# RL7005_IP_SVD register map
Vendor: Realtek
Registers are 32-bit, read-write, reset 0x0 unless marked. A register's access mark holds for its fields unless they carry their own. Offsets are from the block's base; [hi:lo] are bit positions; {n}, {i} and the like mark numbered series.

## PAGE6 (part 1 of 2)
Base 0x40000000
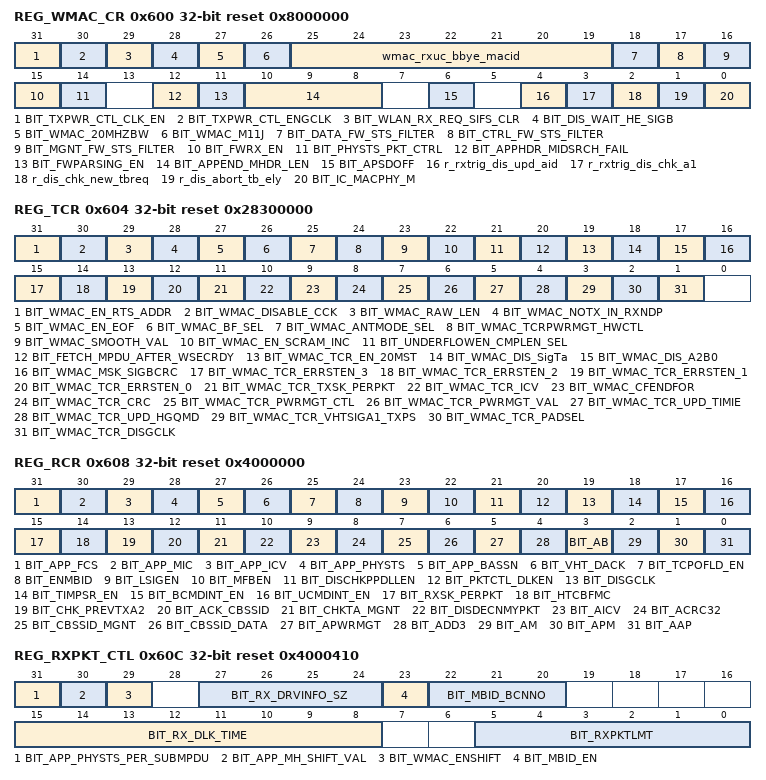
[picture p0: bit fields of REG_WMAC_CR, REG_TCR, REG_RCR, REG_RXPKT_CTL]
0x600 REG_WMAC_CR access per field reset 0x8000000
  [31] BIT_TXPWR_CTL_CLK_EN rw — IF set to 1, txpwr_ctrl clock enable, only work when BIT_TXPWR_CTL_ENGCLK set to 1,
  [30] BIT_TXPWR_CTL_ENGCLK rw — If set to 1, enable txpwr_ctrl clock gating function.
  [29] BIT_WLAN_RX_REQ_SIFS_CLR rw — When set, enable sifs clear wlan_rx_req
  [28] BIT_DIS_WAIT_HE_SIGB rw — When set, will not wait and check he mu sigb and ndp info
  [27] BIT_WMAC_20MHZBW rw
  [26] BIT_WMAC_M11J rw
  [25:19] wmac_rxuc_bbye_macid ro — hw latch macid when rx my unicast bye-bye frame in relay mode 7E:rxpktbuf full 7F:not valid macid
  [18] BIT_DATA_FW_STS_FILTER rw — When this bit is set,Accept data frame in partial length condition. It will take effect when RxFilter3-5 is disabled and RxFilter 0-2 is enabled.
  [17] BIT_CTRL_FW_STS_FILTER rw — When this bit is set,Accept control frame in partial length condition. It will take effect when RxFilter3-5 is disabled and RxFilter 0-2 is enabled.
  [16] BIT_MGNT_FW_STS_FILTER rw — When this bit is set,Accept management frame in partial length condition. It will take effect when RxFilter3-5 is disabled and RxFilter 0-2 is enabled.
  [15] BIT_FWRX_EN rw — Enable to receive pkt into FWFF, default 1'b0. When Fw needs to receive pkt, this bit must be set to 1'b1
  [14] BIT_PHYSTS_PKT_CTRL rw — If set to 1,HW will send interrupt (0x124[26]) only when there is phy status valid fwsts pkt written into FWFF
  [12] BIT_APPHDR_MIDSRCH_FAIL rw — If set to 1, Hw will append 16 bytes MAC header into FWFF when MACID search fail
  [11] BIT_FWPARSING_EN rw — If set to 1, mac header and rx desc of the pkt into rx buff are also received into FWFF.
  [10:8] BIT_APPEND_MHDR_LEN rw — Appended MAC header length, unit in 32 bytes
  [6] BIT_APSDOFF rw — 1:MAC issue sleep signal to disable BB/AFE/RF TRX function. After MAC has finished, APSDOFF_STATUS will report"1". 0:MAC issue wakeup signal to recall BB/AFE/RF back to RX idle mode. After MAC has finished,APSDOFF _STATUS will report "0".
  [4] r_rxtrig_dis_upd_aid rw — 1:will only update aid_fit info when the first trigger in a ppdu is parsered 0:will update aid_fit info every time when two or more trigger aggregate in a ppdu
  [3] r_rxtrig_dis_chk_a1 rw — 1:will not check if A1 of trigger frame is my unicast or broadcast address 0:will check if A1 of trigger frame is my unicast or broadcast address
  [2] r_dis_chk_new_tbreq rw — 1:rxtrig req_in will assert every time when aid fit if two or more trigger aggregate in a ppdu 0:rxtrig req_in will not assert again when there is already a correct trigger received
  [1] r_dis_abort_tb_ely rw — 1:will abort ptcl generating tb data when macrx_active is low 0:will abort ptcl generating tb data when new rxtrig req_in is assert
  [0] BIT_IC_MACPHY_M rw — To make ASIC become BB+RF only, and put out the MAC_PHY interface
0x604 REG_TCR reset 0x28300000 — Transmission Configuration Register
  [31] BIT_WMAC_EN_RTS_ADDR — when set to 1, enable change RTS multicast address
  [30] BIT_WMAC_DISABLE_CCK — when set to 1, disable cck rate packet
  [29] BIT_WMAC_RAW_LEN — 1: use raw ppdu_len 0: use 4byte alignment ppdu_len
  [28] BIT_WMAC_NOTX_IN_RXNDP — 1: block original tx when receiving NDP packet
  [27] BIT_WMAC_EN_EOF — when set to 1, enable single ampdu for qos packet. In early mode,not set to 1.
  [26] BIT_WMAC_BF_SEL — 1: set ndp_rx_standby when rx ppdu of ndpa end; 0: set ndp_rx_standby when rx ndpa packet fcs end;
  [25] BIT_WMAC_ANTMODE_SEL — 0:4x1 mode, 1:8x1 mode
  [24] BIT_WMAC_TCRPWRMGT_HWCTL — If this bit is set to 1, MAC will overwrite power bit of frame control according to PWR_ST. (only for RTS/CTS/ACK/CFEND/BA/BAR frames)
  [23] BIT_WMAC_SMOOTH_VAL — smooth value of plcp header HTSIG2
  [22] BIT_WMAC_EN_SCRAM_INC — Increase 1 in service field scrambler seed per tx end
  [21] BIT_UNDERFLOWEN_CMPLEN_SEL — compare length selector for enable condition of underflow, consider plcp header when set 1
  [20] BIT_FETCH_MPDU_AFTER_WSECRDY — If set to 1,mactx_mpdu_gen will fetch mpdu after wsec is ready when sectype is not tkip/wep40/wep104
  [19] BIT_WMAC_TCR_EN_20MST — when set to 1, enable ndpa signaling TA when BW =20MHz
  [18] BIT_WMAC_DIS_SigTa — when set to 1, disable signaling TA information for response packet
  [17] BIT_WMAC_DIS_A2B0 — when set to 1, not check bit 0 of rx a2
  [16] BIT_WMAC_MSK_SIGBCRC — when set to 1, mask sigb crc in service field for vht packet
  [15] BIT_WMAC_TCR_ERRSTEN_3 — Use phytxend_ps to reset mactx state machine
  [14] BIT_WMAC_TCR_ERRSTEN_2 — If txd fifo underflow when txtype is cmpba, reset mactx state machine
  [13] BIT_WMAC_TCR_ERRSTEN_1 — If txd fifo underflow, reset mactx state machine
  [12] BIT_WMAC_TCR_ERRSTEN_0 — Phytxend_ps comes but mactx still active, reset mactx state machine
  [11] BIT_WMAC_TCR_TXSK_PERPKT — Search key for each mpdu
  [10] BIT_WMAC_TCR_ICV — Integrity Check Value. This bit indicates the existence of an ICV appended to an encipherment packet. 1: No ICV appended 0: ICV appended
  [9] BIT_WMAC_CFENDFOR — CF-End Frame Format.The Address 2 field of CF-End is defined to be the address of the STA contained in the AP, but in 802.11n a STA can also send CF-End.The Address 2 field is not specified clearly in this case. This register chooses between MAC ID of the STA or BSSID of the network. 0: BSSID 1: MAC ID
  [8] BIT_WMAC_TCR_CRC — Append 32-bit Cyclic Redundancy Check. This bit indicates the existence of a CRC32 appended to a packet. 1: No CRC32 appended 0: A CRC32 is appended
  [7] BIT_WMAC_TCR_PWRMGT_CTL — If this bit is set to 1, MAC will overwrite power bit of frame control according to PWR_ST. (only for data frame)
  [6] BIT_WMAC_TCR_PWRMGT_VAL — MAC will overwrite power bit of frame control according to PWR_ST.(only for data frame)
  [5] BIT_WMAC_TCR_UPD_TIMIE — when set to 1, enable hw to update beacon's time field
  [4] BIT_WMAC_TCR_UPD_HGQMD — when set to 1, enable HGQ set moredata bit in Frame control field
  [3] BIT_WMAC_TCR_VHTSIGA1_TXPS — This bit controls TXOP_PS_NOT_ALLOWED bit value of VHT-SIG-A1 field in TX VHT packets 1: TXOP_PS_NOT_ALLOWED is set to 1 0: TXOP_PS_NOT_ALLOWED is set to 0
  [2] BIT_WMAC_TCR_PADSEL — AMPDU Padding pattern selection 0: 32-bit Zero padding, 1: Zero length delimiter.
  [1] BIT_WMAC_TCR_DISGCLK — when set to 1,disable MACTX clock gating control.
0x608 REG_RCR reset 0x4000000 — Receive Configuration Register
  [31] BIT_APP_FCS — When set, wmac RX will append FCS after payload.
  [30] BIT_APP_MIC — When this bit is set to 1, MACRX will retain the MIC at the bottom of the packet. Otherwise, MIC will be removed and reported the status in RXDESC. When a MPDU is encrypted with TKIP without MIC, MACRX will ignore this option, that is, MIC must be remained in back of the plain text.
  [29] BIT_APP_ICV — When this bit is set to 1, MACRX will retain the ICV at the bottom of the packet. Otherwise, MIC will be removed and reported the status in RXDESC.
  [28] BIT_APP_PHYSTS — Append RXFF0 PHY Status Enable When this bit is set, then PHY Status is appended before RX packet in RXFF. When this bit is set, the RX_DRV_INFO_SZ shall be set to include PHY Status report.
  [27] BIT_APP_BASSN — Append SSN of previous TXBA Enable When this bit is set, then SSN of previous TXBA is appended as after original RXDESC as the 4-th DW of RXDESC.
  [26] BIT_VHT_DACK — This bit to control response type for vht single mpdu data packet. 1: ACK as response 0: BA as response
  [25] BIT_TCPOFLD_EN — When set,Enable TCP checksum offload
  [24] BIT_ENMBID — Enable Multiple Bssid. 1: Enable. Only response ACK to the packets whose DID(A1) matching to the addresses in the MBSSID CAM Entries. 0: Disable.
  [23] BIT_LSIGEN — Enable LSIG TXOP Protection function. 1: Enable. Search KEYCAM for each rx packet to check if LSIGEN bit is set. If LSIGEN is set, then sender support LSIG TXOP protection and we need send response with LSIG TXOP protection 0: Disable
  [22] BIT_MFBEN — Enable immediate MCS Feedback function 1: Enable. When Rx packet with MRQ = 1"b1, then search KEYCAM to find sender"s MCS Feedback function and send response 0: Disable
  [21] BIT_DISCHKPPDLLEN — When set,do not check PPDU while the PPDU length is smaller than 14 byte.
  [20] BIT_PKTCTL_DLKEN — When set,while rx path dead lock occurs, reset rx path
  [19] BIT_DISGCLK — When set,disable macrx clock gating control
  [18] BIT_TIMPSR_EN — When set, enable RX Beacon TIM Parser
  [17] BIT_BCMDINT_EN — Broadcast data packet interrupt enable. When this bit is set, this bit is auto clear by MAC. As long as a data type broadcast packet is received, this bit will be set.
  [16] BIT_UCMDINT_EN — Unicast data packet with FC.MD = 1 interrupt enable. When this bit is set, this bit is auto clear by MAC. As long as a data type unicast packet is received, this bit will be set.
  [15] BIT_RXSK_PERPKT — Executing key search per MPDU
  [14] BIT_HTCBFMC — 1: HTC -> MFC 0: MFC-> HTC
  [13] BIT_CHK_PREVTXA2 — When set,enable check rxa1 with txa2.
  [12] BIT_ACK_CBSSID — The field effects behavior of response frame,except TB. 0:Only A1 match to send response frame. 1:A1 match and satisfy BSSID condition will send response frame.
  [11] BIT_CHKTA_MGNT — Check Transmitter_BCN When set to 1, MAC will check the Transmitter Address (A2) of RX beacon or Probe response to determine if this packet belongs to this Transmitter Address (Address 2) . Both in Infrastructure mode and Ad-hoc mode.
  [10] BIT_DISDECNMYPKT — This bit determines whether hw need to do decryption. 1: If A1 match or broadcast, do decryption. 0: Do decryption.
  [9] BIT_AICV — Accept Integrity Check Value Error packets. This bit determines whether packets with ICV errors will be accepted or rejected. 1: Accept 0: Reject
  [8] BIT_ACRC32 — Accept CRC32 Error packets. When set to 1, packets with CRC32 errors will be accepted. When set to 0, packets with CRC32 errors will be rejected. 1: Accept 0: Reject
  [7] BIT_CBSSID_MGNT — Check BSSID_BCN When set to 1, MAC will check the BSSID of RX beacon or Probe response to determine if this packet belongs to this BSSID.
  [6] BIT_CBSSID_DATA — Check BSSID_DATA, To DS, From DS Match Packet. When set to 1, MAC will check the Rx data type frame"s BSSID, To DS, and From DS fields, to determine if it is set to Link OK in an Infrastructure or Ad hoc network. Note this setting is independent of nettype. Driver must set this bit in ad hoc mode and client mode.
  [5] BIT_APWRMGT — Accept Power Management Packet. This bit determines whether the RTL8192D will accept or reject packets with the power management bit set. 1: Accept 0: Reject
  [4] BIT_ADD3 — Accept Address 3 Match Packets. Set this bit to 1 to accept broadcast/multicast data type frames that Address 3 matching RTL8190"s MAC address. This bit is valid only when NETYPE (bit 3-2, MSR) is set to Link OK on an Infrastructure network.
  [3] BIT_AB — Accept Broadcast packets. This bit determines whether broadcast packets will be accepted or rejected. 1: Accept 0: Reject
  [2] BIT_AM — Accept Multicast packets. This bit determines whether multicast packets will be accepted or rejected. 1: Accept 0: Reject
  [1] BIT_APM — Accept Physical Match packets. This bit determines whether physical match packets will be accepted or rejected. 1: Accept 0: Reject
  [0] BIT_AAP — Accept Destination Address packets. This bit determines whether packets with a destination address will be accepted or rejected. 1: Accept 0: Reject
0x60C REG_RXPKT_CTL reset 0x4000410 — RX Packet Control Register
  [31] BIT_APP_PHYSTS_PER_SUBMPDU — When this bit is set to 1,append phy status for each mpdu if phy status is valid. Otherwise,append phy status for each ppdu.
  [30] BIT_APP_MH_SHIFT_VAL — When this bit is set to 1,append MAC header shift value in rx descriptor,otherwise, not append
  [29] BIT_WMAC_ENSHIFT — MAC header shift function enable signal in MACRX
  [27:24] BIT_RX_DRVINFO_SZ — RX DESC Driver Info Size: For RXPKTBUF layout, this field indicates the offset starting from the end of RXDESC to the beginning of RX packet. The unit is 8-byte. This value will be copied to DRV_INFO_SIZE field in RXDESC.
  [23] BIT_MBID_EN
  [22:20] BIT_MBID_BCNNO
  [15:8] BIT_RX_DLK_TIME — macrx dead lock timer timeout value (unit in 4us). As data_on is deasserted and no RXD is received but macrx still waits coming RXD, the deadlock timer will be enabled in this case
  [5:0] BIT_RXPKTLMT — RX PKT Upper Limit. The unit is 512 bytes. When "0", no RX limit is forced.
0x610 REG_MACID — MAC ID Register
  [31:0] BIT_MACID_V1 — MAC Identification Number Register BIT[31:0]
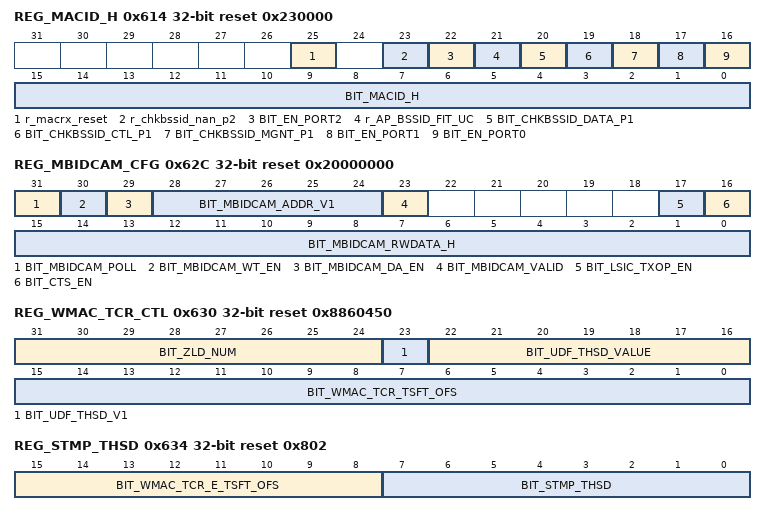
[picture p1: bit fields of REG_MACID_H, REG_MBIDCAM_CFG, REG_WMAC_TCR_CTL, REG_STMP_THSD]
0x614 REG_MACID_H access per field reset 0x230000 — MAC ID Register
  [25] r_macrx_reset wo — set 1 to reset macrx.One pulse
  [23] r_chkbssid_nan_p2 rw — When set 1,enable check port2 bssid.
  [22] BIT_EN_PORT2 rw — When set 1,enable NAN PORT2
  [21] r_AP_BSSID_FIT_UC rw — When set 1,bssid fit when AP port0 rx unciast data packet
  [20] BIT_CHKBSSID_DATA_P1 rw — When set,enable check port1 data frame bssid
  [19] BIT_CHKBSSID_CTL_P1 rw — When set,enable check port1 bssid of trigger/vhtndpa/hendpa/ba
  [18] BIT_CHKBSSID_MGNT_P1 rw — When set,enable check port1 mgnt frame bssid
  [17] BIT_EN_PORT1 rw — When set 1,enable PORT1
  [16] BIT_EN_PORT0 rw — When set 1,enable PORT0
  [15:0] BIT_MACID_H rw — MAC Identification Number Register BIT[47:32]
0x618 REG_BSSID — BSSID Register
  [31:0] BIT_BSSID_V1 — Basic Station Set Identification BIT[31:0]
0x61C REG_BSSID_H — BSSID Register
  [15:0] BIT_BSSID_H — Basic Station Set Identification BIT[47:32]
0x620 REG_MAR — Multicast Address Register
  [31:0] BIT_MAR_V1 — Multicast Address Register BIT[31:0]. The value of this register is written by the driver to specify the type of multicast address supported by RTL8192D. The value is created by a hashed calculation that is also implemented by the hardware for multicast address filtering.
0x624 REG_MAR_H — Multicast Address Register
  [31:0] BIT_MAR_H — Multicast Address Register BIT[63:32].The value of this register is written by the driver to specify the type of multicast address supported by RTL8192D. The value is created by a hashed calculation that is also implemented by the hardware for multicast address filtering.
0x628 REG_MBIDCAMCFG_1 — MBSSID CAM Configuration Register
  [31:0] BIT_MBIDCAM_WDATA_L — BSSID[31:0]
0x62C REG_MBIDCAM_CFG access per field reset 0x20000000 — MBSSID CAM Configuration Register
  [31] BIT_MBIDCAM_POLL wo — Pooling bit.
  [30] BIT_MBIDCAM_WT_EN rw — Write Enable.
  [29] BIT_MBIDCAM_DA_EN rw — CAM Direct Acess Enable
  [28:24] BIT_MBIDCAM_ADDR_V1 rw — CAM Address
  [23] BIT_MBIDCAM_VALID rw — CAM Valid bit.
  [17] BIT_LSIC_TXOP_EN rw — LSIG TXOP enable
  [16] BIT_CTS_EN rw — Dual CTS/CFE enable
  [15:0] BIT_MBIDCAM_RWDATA_H rw — BSSID[47:32]
0x630 REG_WMAC_TCR_CTL reset 0x8860450
  [31:24] BIT_ZLD_NUM — Fetch zero length delimiter number(unit : 4bytes) when mactx underflow
  [23] BIT_UDF_THSD_V1 — BIT_UDF_THSD[7]=1,enable underflow recovery;r_UDF_THSD[7]=0,disable underflow recovery; BIT_UDF_THSD[6:0]: when mac_wrptr - PHY_rdptr is less than this value, set underflow;
  [22:16] BIT_UDF_THSD_VALUE — Underflow threshold
  [15:0] BIT_WMAC_TCR_TSFT_OFS — BIT_WMAC_TCR_TSFT_OFS[7:0] is for cck stamp time offset; BIT_WMAC_TCR_TSFT_OFS[15:8] is for ofdm rate time offset;
0x634 REG_STMP_THSD reset 0x802
  [15:8] BIT_WMAC_TCR_E_TSFT_OFS — BIT_WMAC_TCR_TSFT_OFS[7:0] is for ht/vht/he stamp time offset;
  [7:0] BIT_STMP_THSD — when PHY_rdptr is greater than this value, then latch STMP value from TSFT
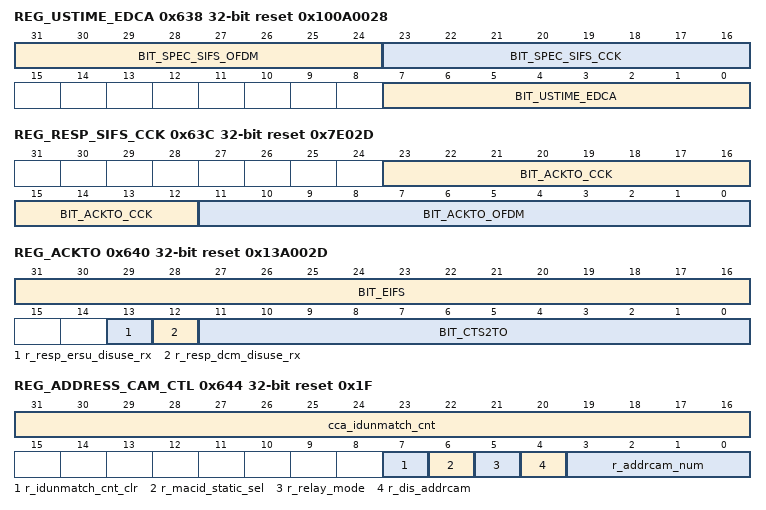
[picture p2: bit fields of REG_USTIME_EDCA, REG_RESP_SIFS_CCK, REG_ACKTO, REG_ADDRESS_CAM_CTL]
0x638 REG_USTIME_EDCA reset 0x100A0028 — US Time Tuning for EDCA Register
  [31:24] BIT_SPEC_SIFS_OFDM — The spec SIFS value for duration calculation
  [23:16] BIT_SPEC_SIFS_CCK — The spec SIFS value for duration calculation
  [7:0] BIT_USTIME_EDCA — Sets the microsecond time unit used by MAC EDCA clock.
0x63C REG_RESP_SIFS_CCK reset 0x7E02D — Response SIFS for CCK Register
  [23:12] BIT_ACKTO_CCK — This register sets the Ack time out value after Tx unicast packet with CCK rate. It is in units of us.
  [11:0] BIT_ACKTO_OFDM — This register sets the Ack time out value after Tx unicast packet. It is in units of us.
0x640 REG_ACKTO reset 0x13A002D — ACK Timeout Register
  [31:16] BIT_EIFS — This register sets the EIFS value mentioned in 802.11 specification. It is in units of us. To receive 1Mbps ACK frame, EIFS = SIFS + 144us (preamble length) + 48us (PLCP header length) + 112us (14 bytes of data) = 314us.
  [13] r_resp_ersu_disuse_rx — 0:rx er su will response tx er su
  [12] r_resp_dcm_disuse_rx — 0:rx dcm will response tx dcm when ctrl info is valid and inf0_dcm=1
  [11:0] BIT_CTS2TO — This register sets the CTS2 time out value after CTS1 in Dual CTS sequence. It is in units of us.
0x644 REG_ADDRESS_CAM_CTL access per field reset 0x1F
  [31:16] cca_idunmatch_cnt ro — macid no match counter for mpdu
  [7] r_idunmatch_cnt_clr wo — when set, generate one pulse and reset cca_idunmatch_cnt
  [6] r_macid_static_sel rw — when set, statistic only A1 match packet;otherwise statistic A1 match and my bc/mc packet for macid_match_no_fcs
  [5] r_relay_mode rw — when set, enable relay mesh function
  [4] r_dis_addrcam rw — when set, disable address cam filter function
  [3:0] r_addrcam_num rw — address filter cam number, up to 16 entries
0x648 REG_TXOPOWNER_L reset 0x80010
  [31:0] r_txopowner_addr_l — txopowner mac address Register BIT[31:0]
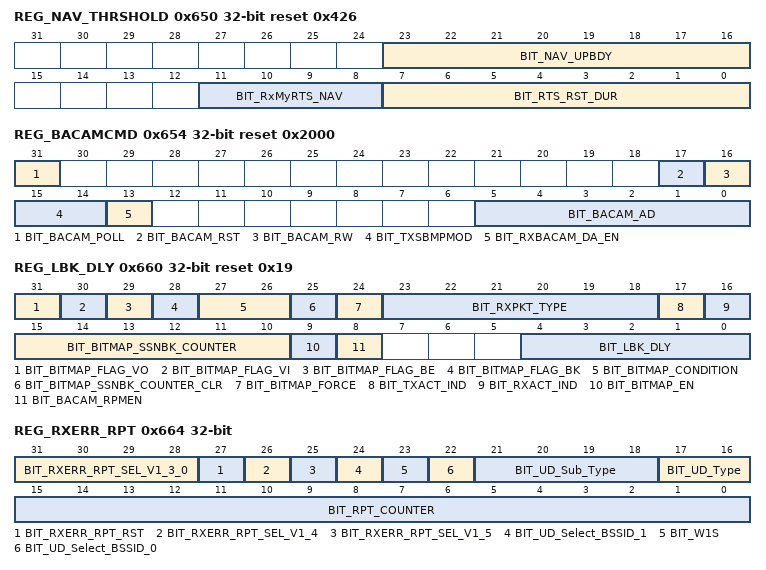
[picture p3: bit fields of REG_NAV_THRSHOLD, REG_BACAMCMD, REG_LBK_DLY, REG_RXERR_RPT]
0x650 REG_NAV_THRSHOLD reset 0x426 — NAV Threshold Register
  [23:16] BIT_NAV_UPBDY — When NAV update is beyond this value, then NAV update is aborted. When this field is 0x00, NAV_UPPER function is disable. The unit is 128us.
  [11:8] BIT_RxMyRTS_NAV — RX my RTS NAV. As rx my unicast RTS and RxMyRTS_NAV is not equal to zero, then rx NAV is set to wait response transition time and RxMyRTS_NAV to avoid contention with the TXOP originator. If RxMyRTS_NAV is equal to zero, this mechanism is disabled
  [7:0] BIT_RTS_RST_DUR — RTS NAV Reset Time. This is the value in us, not including the time of CTS frame, to reset the NAV set by an RTS frame if no PHY indication occurred during this time. Refer to 802.11 1999 Section 9.2.5.4 for detailed description.
0x654 REG_BACAMCMD access per field reset 0x2000 — Block ACK CAM Command Register
  [31] BIT_BACAM_POLL wo — Polling bit BA CAM
  [17] BIT_BACAM_RST ro — Set 1 to reset BA CAM. Hardware will set the invalid bit for all entries. After reset is finished this bit is reset to 0.
  [16] BIT_BACAM_RW rw — Set 1 = Write, set 0 = Read
  [15:14] BIT_TXSBMPMOD rw — Bit[15]: if macrx_dma idle, grant txsbmp_req Bit[14]: if macrx is idle, grant txsbmp_req 00: If FSM is idle, grant txsbmp_req 01: If FSM and mac rx is idle, grant txsbmp_req 10: If FSM and macrx_dma is idle, grant txsbmp_req 11: if FSM, macrx and macrx_dma is idle, grant txsbmp_req
  [13] BIT_RXBACAM_DA_EN rw — CAM Direct Acess enable
  [5:0] BIT_BACAM_AD rw — BA CAM address. Memory is double-word access.
0x658 REG_BACAM_WD — Block ACK CAM Content Register
  [31:0] BIT_BA_CONTENT_L — Used for CAM content read and write access register. Because BA CAM is 64 bit access, the double word (32-bit) responds to the lower 32 bits of CAM content.
0x65C REG_BACAM_WD_H — Block ACK CAM Content Register
  [31:0] BIT_BA_CONTENT_H — Used for CAM content read and write access register. Because BA CAM is 64 bit access, the double word (32-bit) responds to the upper 32 bits of CAM content.
0x660 REG_LBK_DLY access per field reset 0x19 — Loopback Delay Register
  [31] BIT_BITMAP_FLAG_VO ro — When BIT_BITMAP_VO = 1, HW will check received packet's sequence number by BIT_BITMAP_CONDITION, and clear the bit after occur one time which received the correct sequence number.
  [30] BIT_BITMAP_FLAG_VI ro — When BIT_BITMAP_VI = 1, HW will check received packet's sequence number by BIT_BITMAP_CONDITION, and clear the bit after occur one time which received the correct sequence number.
  [29] BIT_BITMAP_FLAG_BE ro — When BIT_BITMAP_BE = 1, HW will check received packet's sequence number by BIT_BITMAP_CONDITION, and clear the bit after occur one time which received the correct sequence number.
  [28] BIT_BITMAP_FLAG_BK ro — When BIT_BITMAP_BK = 1, HW will check received packet's sequence number by BIT_BITMAP_CONDITION, and clear the bit after occur one time which received the correct sequence number.
  [27:26] BIT_BITMAP_CONDITION rw — ADDBA condition: 0: HW start sequence - 64. 1: HW start sequence - 128. 2: HW start sequence - 256. 3: HW start sequence - 512.
  [25] BIT_BITMAP_SSNBK_COUNTER_CLR ro — Clear BIT_BITMAP_SSNBK_COUNTER.
  [24] BIT_BITMAP_FORCE rw — Under the BIT_BITMAP_EN = 1 condition. 1: Rx's packet always checks sequence number by BIT_BITMAP_CONDITION. 0: Disable
  [23:18] BIT_RXPKT_TYPE ro — The type and subtype field of frame control of rx packet
  [17] BIT_TXACT_IND ro — Indicate MAC/PHY is busy to tx packet
  [16] BIT_RXACT_IND ro — Indicate MAC is busy to rx packet
  [15:10] BIT_BITMAP_SSNBK_COUNTER ro — Count the sequence number out of BITMAP condition (0x663[3:2]).
  [9] BIT_BITMAP_EN rw — 1:Enable of counter and WMAC_BITMAP_CTL(0x663) 0:Disable function
  [8] BIT_BACAM_RPMEN rw — 1:Enable repeat mode 0:Disable function
  [4:0] BIT_LBK_DLY rw — Loopback Delay. In unit of 'us'; indicates the delay after which the tdrdy_mac starts. In wep/tkip mode, the delay should be larger than 15, because the initial delay of security is about 1320 cycles, approximately to 16.5 us.
0x664 REG_RXERR_RPT access per field — RX Error Report Register
  [31:28] BIT_RXERR_RPT_SEL_V1_3_0 rw — Rx packet counter report selection bit3~bit0 RXERR_RPT_SEL[25,26,31:28]: Counter description 6'd0: OFDM MPDU OK counter 6'd1: OFDM MPDU Fail counter 6'd2: OFDM False Alarm counter 6'd3: CCK MPDU OK counter 6'd4: CCK MPDU Fail counter 6'd5: CCK False Alarm counter; 6'd6: HT MPDU OK counter 6'd7: HT MPDU Fail counter 6'd8: HT PPDU PLCP ok counter 6'd9: HT False Alarm counter 6'd10: Rx full drop packet counter 6'd11: RSVD 6'd12: user define 0 counter 6'd13: user define 1 counter 6'd14: user define 2 counter 6'd15: user define 3 counter 6'd16: VHT SU MPDU OK counter 6'd17: VHT SU MPDU Fail counter 6'd18: VHT SU PPDU plcp ok counter 6'd19: VHT SU False Alarm counter 6'd20: invalid_pkt counter 6'd21: VHT MU MPDU OK counter 6'd22: VHT MU MPDU Fail counter 6'd23: VHT MU PPDU plcp ok counter 6'd24: VHT MU False Alarm counter 6'd25: HE SU MPDU OK counter 6'd26: HE SU MPDU Fail counter 6'd27: HE SU PPDU plcp ok counter 6'd28: HE SU False Alarm counter 6'd29: HE MU MPDU OK counter 6'd30: HE MU MPDU Fail counter 6'd31: HE MU PPDU plcp ok counter 6'd32: HE MU False Alarm counter 6'd33: drop packet counter
  [27] BIT_RXERR_RPT_RST wo — Write "1" to set the counter to zero. One pulse
  [26] BIT_RXERR_RPT_SEL_V1_4 rw — Rx packet counter report selection bit4
  [25] BIT_RXERR_RPT_SEL_V1_5 rw — Rx packet counter report selection bit5
  [24] BIT_UD_Select_BSSID_1 rw — {24,22} Select matched BSSID: 2'b0: Port 0 2'b1: Port 1 otherwise, do not care bssid match or not
  [23] BIT_W1S rw — Write One Setting, it is only valid for RXERR_RPT_SEL (4'd12 ~ 4'd15)
  [22] BIT_UD_Select_BSSID_0 rw — Select BSSID bit0
  [21:18] BIT_UD_Sub_Type rw — User defined: SubType
  [17:16] BIT_UD_Type rw — User defined: Type
  [15:0] BIT_RPT_COUNTER rw — The reported counter value corresponding to Report type selected.
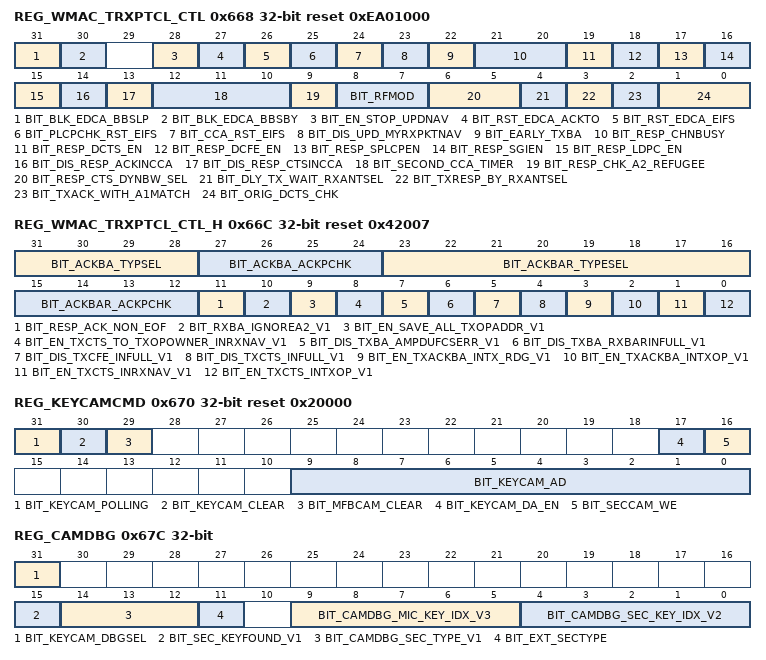
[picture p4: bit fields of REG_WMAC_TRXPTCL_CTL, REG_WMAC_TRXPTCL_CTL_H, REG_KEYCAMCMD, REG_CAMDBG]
0x668 REG_WMAC_TRXPTCL_CTL reset 0xEA01000 — WMAC TX/RX Protocol Control Register
  [31] BIT_BLK_EDCA_BBSLP — Block EDCA Tx while BB in sleep state
  [30] BIT_BLK_EDCA_BBSBY — Block EDCA Tx while BB in standby state
  [28] BIT_EN_STOP_UPDNAV — When this bit set 1. If RX packet with EDCA_REF is low, not update NAV.
  [27] BIT_RST_EDCA_ACKTO — While in ACKTO duration, reset scheduler top to TX
  [26] BIT_RST_EDCA_EIFS — While in EIFS duration, reset scheduler top to TX
  [25] BIT_PLCPCHK_RST_EIFS — Reset EIFS counter while receive correct PLCP.
  [24] BIT_CCA_RST_EIFS — Reset EIFS counter while CCA on
  [23] BIT_DIS_UPD_MYRXPKTNAV — Do not update NAV, while receiving my packet.
  [22] BIT_EARLY_TXBA — While phyrxon down, mac_rxactive on. Ignore mac rx busy, respond BA immediately.
  [21:20] BIT_RESP_CHNBUSY — Define channel busy condition in responder to determine RX busy 1: PHYRXON (OFDM_VBON/CCKCCA) 0: CCA (CCKCCA/OFDMCCA)
  [19] BIT_RESP_DCTS_EN — Enable responder send dual CTS for responding Rx RTS
  [18] BIT_RESP_DCFE_EN — Enable responder send dual CF-END for responding RX CF-END
  [17] BIT_RESP_SPLCPEN — Enable responder send SPLCP CCK response for acknowledging Rx SPLCP CCK packet
  [16] BIT_RESP_SGIEN — Enable responder send SGI HT-OFDM response for acknowledging Rx SGI HT-OFDM packet
  [15] BIT_RESP_LDPC_EN — if rxpkt with ldpc, response pkt with ldpc
  [14] BIT_DIS_RESP_ACKINCCA — Disable to response ack when cca goes high after SIFS
  [13] BIT_DIS_RESP_CTSINCCA — 8812 Disable to response cts when cca goes high after SIFS
  [12:10] BIT_SECOND_CCA_TIMER — 8812 The maximum time interval in us that secondary cca is pull high before primary cca When receive duplicated rts. When station response with cts, if the time that secondary cca pull high before primary cca is larger than this threshold, then secondary cca is judged to be interference, otherwise it is judged to the received RTS frame. default: 3"b0
  [9] BIT_RESP_CHK_A2_REFUGEE — if port 1 isacting as AP,this bit should set 0,otherwise should set 1 if relay mode enable and port1 is not AP mode
  [8:7] BIT_RFMOD — 8812 RF_BW indication, Used to decide response duplicated cts txsc 2"b00: 20M, 2"b01: 40M, 2"b10: 80M e.g: when RF_BW= 80M, duplicated cts BW= 40M, txsc = 9 or 10 when RF_BW = 40M, duplicated cts BW = 40M, txsc = 0
  [6:5] BIT_RESP_CTS_DYNBW_SEL — 8812 Response cts bw selection when dynamic rts frame is received 00: current maximum bw indicated by secondary cca 01: bw fall back by one level based on bw in 2"b00 if not reach 20M 10: bw fall back by one level based on bw in 2"b01 if not reach 20M 11: bw fall back by one level based on bw in 2"b10 if not reach 20M e.g, current maximum bw indicated by secondary_cca is 80M, when set to 2"b00, the response cts bw is 80M, when set to 2"b01, cts bw is 40M, when set to 2"b10 or 2"b11 , cts bw is 20M
  [4] BIT_DLY_TX_WAIT_RXANTSEL — 8188E/8812 In some Cases, the phy status may be received too late to be used in the response frame. Enable this bit to postpone the tx of response frame until the phy status is obtained. Otherwise, If the phy status unavailable for its delay, The IOREG value of 0x06D8[6] will be used as before.
  [3] BIT_TXRESP_BY_RXANTSEL — 8188E/8812 Enable responder send the response frame with the antenna selection information which from the phy status of the previous rx frame.
  [2] BIT_TXACK_WITH_A1MATCH — SET TO 1 :check every bit of a1 of rxpkt when need to response
  [1:0] BIT_ORIG_DCTS_CHK — Txok condition for dual CTS frame exchange: 00: Either one Rx ok 01: 1st one Rx ok 10: 2nd one Rx ok 11: both Rx ok
0x66C REG_WMAC_TRXPTCL_CTL_H reset 0x42007 — WMAC TX/RX Protocol Control Register Higher Bit
  [31:28] BIT_ACKBA_TYPSEL — Determine response type for RX BA, and the definition as the bellow 0: NAV 1: Send ACK ACKBA_TYPESEL[0]: used for Basic BA ACKBA_TYPESEL[1]: used for Compression BA ACKBA_TYPESEL[2]: RSVD ACKBA_TYPESEL[3]: used for MTID BA
  [27:24] BIT_ACKBA_ACKPCHK — If set 1, then check ACK Policy of BA control field to determine whether send response or not. When this bit set to 1 and a. ACK Policy of Rx BA control field is 0, then response type is controlled by ACLBA_TYPESEL. b. ACK Policy of Rx BA control field is 1, then don't send response If set 0, then ignore the ACK policy of RX BA control field and response type controlled by ACKBA_TYPESEL ACKBA_ACKPCHK[0]: used for Basic BA ACKBA_ACKPCHK[1]: used for Compression BA ACKBA_ACKPCHK[2]: RSVD ACKBA_ACKPCHK[3]: used for MTID BA
  [23:16] BIT_ACKBAR_TYPESEL — Determine response type for RX BAR, and the definition as the bellow 00: NAV 01: Send BA 10: Send ACK ACKBAR_TYPESEL[1:0]: used for Basic BAR ACKBAR_TYPESEL[3:2]: used for Compression BAR ACKBAR_TYPESEL[5:4]: RSVD ACKBAR_TYPESEL[7:6]: used for MTID BAR
  [15:12] BIT_ACKBAR_ACKPCHK — If set 1, then check ACK Policy of BAR control field to determine whether send response or not. When this bit set to 1 and a. ACK Policy of Rx BAR control field is 0, then response type is controlled by ACLBAR_TYPESEL. b. ACK Policy of Rx BAR control field is 1, then don't send response If set 0, then ignore the ACK policy of RX BAR control field and response type controlled by ACKBA_TYPESEL ACKBA_ACKPCHK[0]: used for Basic BAR ACKBA_ACKPCHK[1]: used for Compression BAR ACKBA_ACKPCHK[2]: RSVD ACKBA_ACKPCHK[3]: used for MTID BAR
  [11] BIT_RESP_ACK_NON_EOF — response to trigger+mgt with eof=0
  [10] BIT_RXBA_IGNOREA2_V1 — Disable check A2 field of RX BA
  [9] BIT_EN_SAVE_ALL_TXOPADDR_V1
  [8] BIT_EN_TXCTS_TO_TXOPOWNER_INRXNAV_V1 — together with bit41, implement 802.11ac txop owner function
  [7] BIT_DIS_TXBA_AMPDUFCSERR_V1 — Disable to send BA for responding RX AMPDU with FCS error subframe
  [6] BIT_DIS_TXBA_RXBARINFULL_V1 — Disable to send BA for responding RX control wrapper BAR dropped by rxpkbuffer full
  [5] BIT_DIS_TXCFE_INFULL_V1 — Disable to send CF-END for responding RX control wrapper CF-END dropped by rxpktbuffer full. This bit is valid when RESP_DCFE_EN is set to 1
  [4] BIT_DIS_TXCTS_INFULL_V1 — Disable to send CTS for responding RX control wrapper RTS dropped by rxpktbuffer full
  [3] BIT_EN_TXACKBA_INTX_RDG_V1 — If this bit is set, then MAC will Tx ACK/BA to respond previous rx my unicast packets send by another STA during TX RDG
  [2] BIT_EN_TXACKBA_INTXOP_V1 — If this bit is set, then MAC will Tx ACK/BA to respond previous rx my unitcast packets send by another STA during my TXOP
  [1] BIT_EN_TXCTS_INRXNAV_V1 — Enable to send CTS in Rx NAV
  [0] BIT_EN_TXCTS_INTXOP_V1 — Enable to send CTS for responding RX RTS during our TXOP period
0x670 REG_KEYCAMCMD access per field reset 0x20000 — CAM Command Register
  [31] BIT_KEYCAM_POLLING ro — Security CAM Polling
  [30] BIT_KEYCAM_CLEAR ro — Set to 1 to clear all valid bits in CAM. After reset will self clear to 0.
  [29] BIT_MFBCAM_CLEAR ro — Write 1 to clear all MFB value in CAM to 7'h7F. After reset will self clear to 0
  [17] BIT_KEYCAM_DA_EN rw — Security CAM Direct Acess Enable
  [16] BIT_SECCAM_WE rw — Security CAM Write Enable
  [9:0] BIT_KEYCAM_AD rw — Security CAM Address Offset CAM address is organized into 8 double-words/entry.
0x674 REG_KEYCAM_WD — Security CAM Content Register
  [31:0] BIT_KEYCAM_WDATA — Security CAM Write Content
0x678 REG_CAMREAD — CAM Read Register
  [31:0] BIT_CAMR_DATA — Security CAM Read Content
0x67C REG_CAMDBG access per field — CAM Debug Register
  [31] BIT_KEYCAM_DBGSEL rw — Select TX/RX CAM Information. Set to 1 to retrieve latest Tx search result. Set to 0 to retrieve latest Rx search result.
  [15] BIT_SEC_KEYFOUND_V1 ro — Security Key Found in CAM 0: key not found 1: key found
  [14:12] BIT_CAMDBG_SEC_TYPE_V1 ro — Found security key type
  [11] BIT_EXT_SECTYPE ro — Found security key ext_sectype
  [9:5] BIT_CAMDBG_MIC_KEY_IDX_V3 ro — Mic KEY INDEX
  [4:0] BIT_CAMDBG_SEC_KEY_IDX_V2 ro — Security KEY INDEX
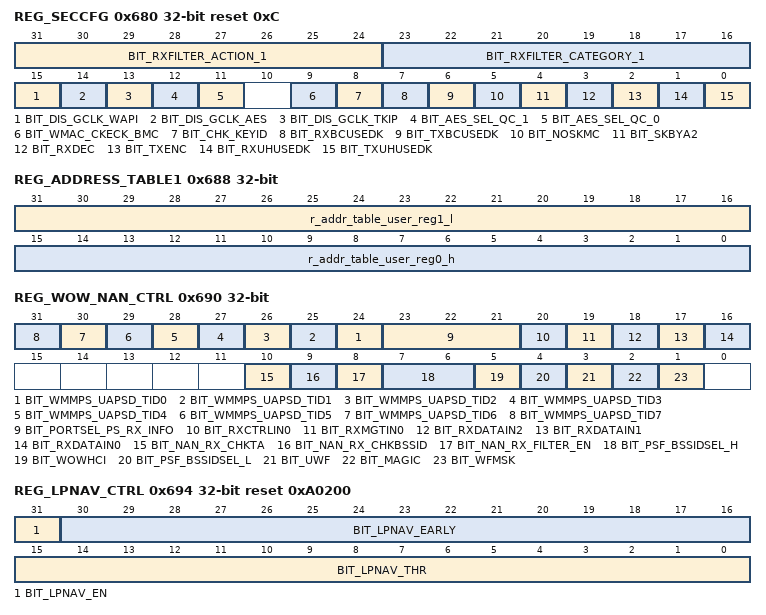
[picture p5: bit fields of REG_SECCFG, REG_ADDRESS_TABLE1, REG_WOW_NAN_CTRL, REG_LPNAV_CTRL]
0x680 REG_SECCFG reset 0xC — Security Configuration Register
  [31:24] BIT_RXFILTER_ACTION_1 — Configured by FW, Refer to 0x68E[10] to decide accepting this frame or not
  [23:16] BIT_RXFILTER_CATEGORY_1 — Configured by FW, Refer to 0x68E[10] to decide accepting this frame or not
  [15] BIT_DIS_GCLK_WAPI — Disable gated clock control for WAPI engine
  [14] BIT_DIS_GCLK_AES — Disable gated clock control for AES engine.
  [13] BIT_DIS_GCLK_TKIP — Disable gated clock control for WEP/TKIP engine.
  [12] BIT_AES_SEL_QC_1 — 1: use QC[7] to compute mic 0: not use QC[7] to compute mic
  [11] BIT_AES_SEL_QC_0 — 1:use QC[7] to compute ctr 0: not use QC[7] to compute ctr
  [9] BIT_WMAC_CKECK_BMC — If this bit is set to 1, key search engine need to check if broadcast/multicast bit matched.
  [8] BIT_CHK_KEYID — If this bit is set to 1, key search engine need to check if key ID matched. If this bit is set to 0, then key ID table must be filled with 2"b00.
  [7] BIT_RXBCUSEDK — Force RX Broadcast packets Use Default Key If this bit is set to 1, use default key for RX key search when received packet is broadcast and multicast.
  [6] BIT_TXBCUSEDK — Force Tx Broadcast packets Use Default Key If this bit is set to 1, use default key for TX key search when transmitted packet is broadcast and multicast.
  [5] BIT_NOSKMC — No Key Search for Multicast Setting 1 to disable key search for multicast frames. Used in MBSSID AP mode. Software should manage security encryption and decryption.
  [4] BIT_SKBYA2 — Search Key by A2 Setting 1 to search security CAM by address 2 for TX and search CAM by address 1 for RX. Setting 0 to search security CAM by address 1 for TX and search CAM by address 2 for RX. Used in MBSSID client mode.
  [3] BIT_RXDEC — Enable Rx Decryption Setting 1 to enable Rx hardware decryption.
  [2] BIT_TXENC — Enable Tx Encryption Setting to 1 to enable Tx hardware encryption.
  [1] BIT_RXUHUSEDK — Force RX Unicast Use Default Key If this bit is set to 1, use default key for RX key search when pairwise key is not found.
  [0] BIT_TXUHUSEDK — Force Tx Unicast Use Default Key If this bit is set to 1, use default key for TX key search when pairwise key is not found.
0x684 REG_ADDRESS_TABLE0
  [31:0] r_addr_table_user_reg0_l — low 32 bit of address table reg0
0x688 REG_ADDRESS_TABLE1
  [31:16] r_addr_table_user_reg1_l — low 16 bit of address table reg1
  [15:0] r_addr_table_user_reg0_h — high 16 bit of address table reg0
0x68C REG_ADDRESS_TABLE2
  [31:0] r_addr_table_user_reg1_h — high 32 bit of address table reg1
0x690 REG_WOW_NAN_CTRL access per field — Wake On WLAN and NAN Control Register
  [n+24] BIT_WMMPS_UAPSD_TID{n} rw (n=0..7) — Disable interrupt 8051 when rx WMMPS UAPSD Qos data with TID{n}
  [23:21] BIT_PORTSEL_PS_RX_INFO rw — The selector for the source of PS RX information (0x692[4:0]). 0 for port 0, 1 for clint0, 2 for clint1, 3 for clint2, 4 for clint3.
  [20] BIT_RXCTRLIN0 ro — It is set to 1 if NIC received control frame with correct DA.
  [19] BIT_RXMGTIN0 ro — It is set to 1 if NIC received management frame with correct BSSID and DA (including unicast and BMC).
  [18] BIT_RXDATAIN2 ro — It is set to 1 if NIC received data frame with correct BSSID and DA (including unicast and BMC).
  [17] BIT_RXDATAIN1 ro — It is set to 1 if NIC received data frame with correct BSSID and DA (including unicast and BMC).
  [16] BIT_RXDATAIN0 ro — It is set to 1 if NIC received data frame with correct BSSID and DA (including unicast and BMC).
  [10] BIT_NAN_RX_CHKTA rw — Enable bit for check TSF filter When set to 1, the TSF address filter will enable. When set to 0, the TSF address filter will disable.
  [9] BIT_NAN_RX_CHKBSSID rw — Check BSSID_BCN for TSF When set to 1, MAC will check the BSSID (A3) of RX beacon or Probe to determine if this packet will sync TSF or not
  [8] BIT_NAN_RX_FILTER_EN rw — When set to 1, the TSF address filter will enable. When set to 0, the TSF address filter will disable.
  [7:6] BIT_PSF_BSSIDSEL_H rw — Bit 1,2 of Select to check the MACID of which port for the WMAC PSF NSARP function. 0: to check the MACID of port0; 1: to check the MACID of port1. 2: to check the MACID of port2. 3: to check the MACID of port3. 4: to check the MACID of port4.
  [5] BIT_WOWHCI rw — This bit is set to allow wake host as wake on wlan event occurring
  [4] BIT_PSF_BSSIDSEL_L rw — Bit 0 of Select to check the MACID of which port for the WMAC PSF NSARP function. 0: to check the MACID of port0; 1: to check the MACID of port1. 2: to check the MACID of port2. 3: to check the MACID of port3. 4: to check the MACID of port4.
  [3] BIT_UWF rw — Unicast Packet. 1: Enable to check packet"s DA match MAC address or not. 0: Disable. (default value)
  [2] BIT_MAGIC rw — Magic Packet. This bit is valid when the PMEn bit of the PMR register is set. The RTL8192 will assert the PMEB signal to wakeup the operating system when a Magic Packet is received. Once the RTL8192 has been enabled for Magic Packet wakeup, it scans incoming packets addressed to the node for a data sequence. The correct sequence indicates to the controller that this is a Magic Packet frame. A Magic Packet frame must also meet the basic requirements: Frame Control + Duration/ID + Destination address + Address 2 + Address 3 + Sequence Control + data + CRC. The destination address may be the node ID of the receiving station or a multicast address, including the broadcast address. The specific sequence consists of 16 duplications of 6 byte ID registers, with no breaks or interrupts. This sequence can be located anywhere within the packet, but must be preceded by a synchronization stream, 6 bytes of FFh. The device will also accept a multicast address, as long as the 16 duplications of the IEEE address match the address of the ID registers. If the Node ID is 11h 22h 33h 44h 55h 66h, then the magic frame"s format is as follows: Frame Control + Duration/ID + Destination address + Address 2 + Address 3 + Sequence Control + MISC + FF FF FF FF FF FF + MISC + 11 22 33 44 55 66 + 11 22 33 44 55 66 + 11 22 33 44 55 66 + 11 22 33 44 55 66 + 11 22 33 44 55 66 + 11 22 33 44 55 66 + 11 22 33 44 55 66 + 11 22 33 44 55 66 + 11 22 33 44 55 66 + 11 22 33 44 55 66 + 11 22 33 44 55 66 + 11 22 33 44 55 66 + 11 22 33 44 55 66 + 11 22 33 44 55 66 + 11 22 33 44 55 66 + 11 22 33 44 55 66 + MISC + CRC.
  [1] BIT_WFMSK rw — WoW function on or off.
0x694 REG_LPNAV_CTRL reset 0xA0200 — Low Power NAV Control Register
  [31] BIT_LPNAV_EN — Low Power NAV Mode Enable. When this bit is set, enable MAC low power NAV mode
  [30:16] BIT_LPNAV_EARLY — When in LPNAV mode, MAC will recall BB and RF into RX idle mode. The unit is us.
  [15:0] BIT_LPNAV_THR — When protected NAV in the received frame is greater than this threshold value, then MAC enters into LPNAV mode. The time unit is 16us.
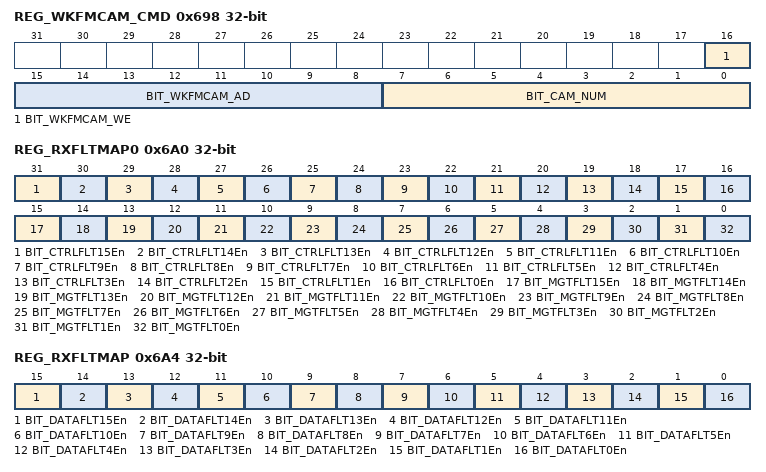
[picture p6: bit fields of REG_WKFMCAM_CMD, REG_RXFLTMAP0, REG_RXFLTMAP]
0x698 REG_WKFMCAM_CMD — Wakeup Frame CAM Number Register
  [16] BIT_WKFMCAM_WE — CAM Write Enable
  [15:8] BIT_WKFMCAM_AD — Entry address
  [7:0] BIT_CAM_NUM — CAM Entry Number
0x69C REG_WKFMCAM_WD — Wakeup Frame CAM CONTENT Register
  [31:0] BIT_WKFMCAM_WD — CAM Write Data
0x6A0 REG_RXFLTMAP0 — RX Filter Map Group 0
  [31] BIT_CTRLFLT15En — When set, frames with type=01 and subtype=1111 are received into RXFF
  [30] BIT_CTRLFLT14En — When set, frames with type=01 and subtype=1110 are received into RXFF
  [29] BIT_CTRLFLT13En — When set, frames with type=01 and subtype=1101 are received into RXFF.
  [28] BIT_CTRLFLT12En — When set, frames with type=01 and subtype=1100 are received into RXFF.
  [27] BIT_CTRLFLT11En — When set, frames with type=01 and subtype=1011 are received into RXFF
  [26] BIT_CTRLFLT10En — When set, frames with type=01 and subtype=1010 are received into RXFF.
  [25] BIT_CTRLFLT9En — When set, frames with type=01 and subtype=1001 are received into RXFF
  [24] BIT_CTRLFLT8En — When set, frames with type=01 and subtype=1000 are received into RXFF
  [23] BIT_CTRLFLT7En — When set, frames with type=01 and subtype=0111 are received into RXFF
  [22] BIT_CTRLFLT6En — When set, frames with type=01 and subtype=0110 are received into RXFF.
  [21] BIT_CTRLFLT5En — When set, frames with type=01 and subtype=0101 are received into RXFF.
  [20] BIT_CTRLFLT4En — When set, frames with type=01 and subtype=0100 are received into RXFF.
  [19] BIT_CTRLFLT3En — When set, frames with type=01 and subtype=0011 are received into RXFF.
  [18] BIT_CTRLFLT2En — When set, frames with type=01 and subtype=0010 are received into RXFF.
  [17] BIT_CTRLFLT1En — When set, frames with type=01 and subtype=0001 are received into RXFF.
  [16] BIT_CTRLFLT0En — When set, frames with type=01 and subtype=0000 are received into RXFF.
  [15] BIT_MGTFLT15En — When set, frames with type=00 and subtype=1111 are received into RXFF.
  [14] BIT_MGTFLT14En — When set, frames with type=00 and subtype=1110 are received into RXFF.
  [13] BIT_MGTFLT13En — When set, frames with type=00 and subtype=1101 are received into RXFF.
  [12] BIT_MGTFLT12En — When set, frames with type=00 and subtype=1100 are received into RXFF.
  [11] BIT_MGTFLT11En — When set, frames with type=00 and subtype=1011 are received into RXFF.
  [10] BIT_MGTFLT10En — When set, frames with type=00 and subtype=1010 are received into RXFF
  [9] BIT_MGTFLT9En — When set, frames with type=00 and subtype=1001 are received into RXFF.
  [8] BIT_MGTFLT8En — When set, frames with type=00 and subtype=1000 are received into RXFF
  [7] BIT_MGTFLT7En — When set, frames with type=00 and subtype=0111 are received into RXFF.
  [6] BIT_MGTFLT6En — When set, frames with type=00 and subtype=0110 are received into RXFF.
  [5] BIT_MGTFLT5En — When set, frames with type=00 and subtype=0101 are received into RXFF
  [4] BIT_MGTFLT4En — When set, frames with type=00 and subtype=0100 are received into RXFF.
  [3] BIT_MGTFLT3En — When set, frames with type=00 and subtype=0011 are received into RXFF
  [2] BIT_MGTFLT2En — When set, frames with type=00 and subtype=0010 are received into RXFF
  [1] BIT_MGTFLT1En — When set, frames with type=00 and subtype=0001 are received into RXFF
  [0] BIT_MGTFLT0En — When set, frames with type=00 and subtype=0000 are received into RXFF
0x6A4 REG_RXFLTMAP — RX Filter Map Group 1
  [15] BIT_DATAFLT15En — When set, frames with type=10 and subtype=1111 are received into RXFF
  [14] BIT_DATAFLT14En — When set, frames with type=10 and subtype=1110 are received into RXFF
  [13] BIT_DATAFLT13En — When set, frames with type=10 and subtype=1101 are received into RXFF.
  [12] BIT_DATAFLT12En — When set, frames with type=10 and subtype=1100 are received into RXFF.
  [11] BIT_DATAFLT11En — When set, frames with type=10 and subtype=1011 are received into RXFF.
  [10] BIT_DATAFLT10En — When set, frames with type=10 and subtype=1010 are received into RXFF.
  [9] BIT_DATAFLT9En — When set, frames with type=10 and subtype=1001 are received into RXFF
  [8] BIT_DATAFLT8En — When set, frames with type=10 and subtype=1000 are received into RXFF
  [7] BIT_DATAFLT7En — When set, frames with type=10 and subtype=0111 are received into RXFF.
  [6] BIT_DATAFLT6En — When set, frames with type=10 and subtype=0110 are received into RXFF
  [5] BIT_DATAFLT5En — When set, frames with type=10 and subtype=0101 are received into RXFF
  [4] BIT_DATAFLT4En — When set, frames with type=10 and subtype=0100 are received into RXFF.
  [3] BIT_DATAFLT3En — When set, frames with type=10 and subtype=0011 are received into RXFF
  [2] BIT_DATAFLT2En — When set, frames with type=10 and subtype=0010 are received into RXFF.
  [1] BIT_DATAFLT1En — When set, frames with type=10 and subtype=0001 are received into RXFF.
  [0] BIT_DATAFLT0En — When set, frames with type=10 and subtype=0000 are received into RXFF.
